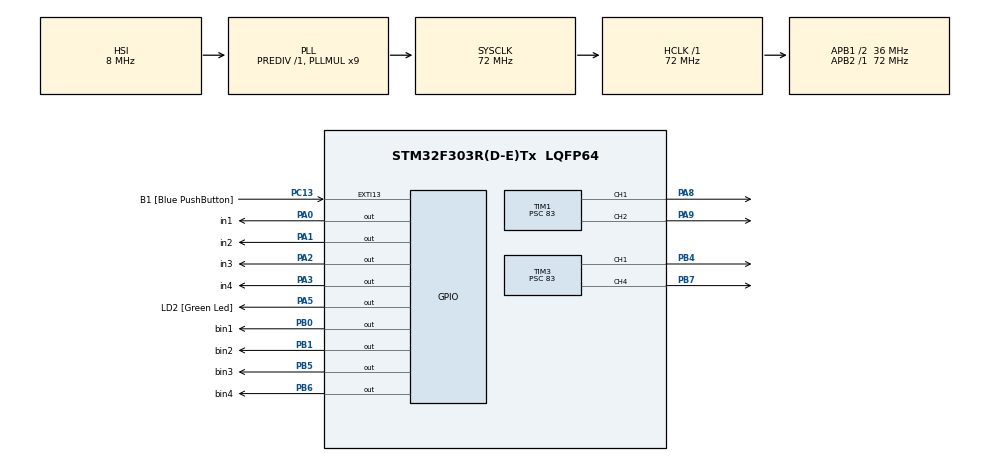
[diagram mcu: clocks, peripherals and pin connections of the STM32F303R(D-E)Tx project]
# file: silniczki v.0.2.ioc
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Mcu.Family=STM32F3
Mcu.Name=STM32F303R(D-E)Tx
Mcu.Package=LQFP64
NVIC.PriorityGroup=NVIC_PRIORITYGROUP_0
PA0.GPIO_Label=in1
PA0.Signal=GPIO_Output
PA1.GPIO_Label=in2
PA1.Signal=GPIO_Output
PA13.GPIO_Label=TMS
PA13.Mode=Serial_Wire
PA13.Signal=SYS_JTMS-SWDIO
PA14.GPIO_Label=TCK
PA14.Mode=Serial_Wire
PA14.Signal=SYS_JTCK-SWCLK
PA2.GPIO_Label=in3
PA2.Signal=GPIO_Output
PA3.GPIO_Label=in4
PA3.Signal=GPIO_Output
PA5.GPIO_Label=LD2 [Green Led]
PA5.GPIO_Mode=GPIO_MODE_OUTPUT_PP
PA5.GPIO_PuPd=GPIO_NOPULL
PA5.GPIO_Speed=GPIO_SPEED_FREQ_LOW
PA5.Signal=GPIO_Output
PA8.Signal=S_TIM1_CH1
PA9.Signal=S_TIM1_CH2
PB0.GPIO_Label=bin1
PB0.Signal=GPIO_Output
PB1.GPIO_Label=bin2
PB1.Signal=GPIO_Output
PB3.GPIO_Label=SWO
PB3.Signal=SYS_JTDO-TRACESWO
PB4.Signal=S_TIM3_CH1
PB5.GPIO_Label=bin3
PB5.Signal=GPIO_Output
PB6.GPIO_Label=bin4
PB6.Signal=GPIO_Output
PB7.Signal=S_TIM3_CH4
PC13.GPIO_Label=B1 [Blue PushButton]
PC13.GPIO_ModeDefaultEXTI=GPIO_MODE_IT_FALLING
PC13.Signal=GPXTI13
PC14-OSC32_IN.Mode=LSE-External-Oscillator
PC14-OSC32_IN.Signal=RCC_OSC32_IN
PC15-OSC32_OUT.Mode=LSE-External-Oscillator
PC15-OSC32_OUT.Signal=RCC_OSC32_OUT
PF0-OSC_IN.Mode=HSE-External-Clock-Source
PF0-OSC_IN.Signal=RCC_OSC_IN
PF1-OSC_OUT.Signal=RCC_OSC_OUT
ProjectManager.HeapSize=0x200
ProjectManager.StackSize=0x400
ProjectManager.TargetToolchain=STM32CubeIDE
RCC.AHBFreq_Value=72000000
RCC.APB1CLKDivider=RCC_HCLK_DIV2
RCC.APB1Freq_Value=36000000
RCC.APB1TimFreq_Value=72000000
RCC.APB2Freq_Value=72000000
RCC.APB2TimFreq_Value=72000000
RCC.CortexFreq_Value=72000000
RCC.HCLKFreq_Value=72000000
RCC.HSE_VALUE=8000000
RCC.HSI_VALUE=8000000
RCC.PLLM=8
RCC.PLLMUL=RCC_PLL_MUL9
RCC.PLLN=336
RCC.PLLP=RCC_PLLP_DIV4
RCC.PLLQ=7
RCC.RCC_PLLsource_Clock_Source_FROM_HSE=RCC_HSE_PREDIV_DIV2
RCC.SYSCLKFreq_VALUE=72000000
RCC.SYSCLKSourceVirtual=RCC_SYSCLKSOURCE_PLLCLK
RCC.USBFreq_Value=72000000
SH.S_TIM1_CH1.0=TIM1_CH1,PWM Generation1 CH1
SH.S_TIM1_CH2.0=TIM1_CH2,PWM Generation2 CH2
SH.S_TIM3_CH1.0=TIM3_CH1,PWM Generation1 CH1
SH.S_TIM3_CH4.0=TIM3_CH4,PWM Generation4 CH4
TIM1.AutoReloadPreload=TIM_AUTORELOAD_PRELOAD_ENABLE
TIM1.Channel-PWM\ Generation1\ CH1=TIM_CHANNEL_1
TIM1.Channel-PWM\ Generation2\ CH2=TIM_CHANNEL_2
TIM1.Period=1000
TIM1.Prescaler=83
TIM3.AutoReloadPreload=TIM_AUTORELOAD_PRELOAD_ENABLE
TIM3.Channel-PWM\ Generation1\ CH1=TIM_CHANNEL_1
TIM3.Channel-PWM\ Generation4\ CH4=TIM_CHANNEL_4
TIM3.Period=1000
TIM3.Prescaler=83
VP_TIM1_VS_ClockSourceINT.Mode=Internal
VP_TIM3_VS_ClockSourceINT.Mode=Internal
board=NUCLEO-F303RE

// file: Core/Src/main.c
/* USER CODE BEGIN Header */
/**
  ******************************************************************************
  * @file           : main.c
  * @brief          : Main program body
  ******************************************************************************
  * @attention
  *
  * Copyright (c) 2025 STMicroelectronics.
  * All rights reserved.
  *
  * This software is licensed under terms that can be found in the LICENSE file
  * in the root directory of this software component.
  * If no LICENSE file comes with this software, it is provided AS-IS.
  *
  ******************************************************************************
  */
/* USER CODE END Header */
#include "main.h"

TIM_HandleTypeDef htim1;
TIM_HandleTypeDef htim3;

void SystemClock_Config(void);
static void MX_GPIO_Init(void);
static void MX_TIM1_Init(void);
static void MX_TIM3_Init(void);

int main(void)
{
  HAL_Init();
  SystemClock_Config();
  MX_GPIO_Init();
  MX_TIM1_Init();
  MX_TIM3_Init();

  /* Infinite loop */
  /* USER CODE BEGIN WHILE */
  while (1)
  {
	  // Silnik M1 do przodu
	  HAL_GPIO_WritePin(in1_GPIO_Port, in1_Pin, GPIO_PIN_SET);
	  HAL_GPIO_WritePin(in2_GPIO_Port, in2_Pin, GPIO_PIN_RESET);

	  // Silnik M2 do tyłu
	  HAL_GPIO_WritePin(in3_GPIO_Port, in3_Pin, GPIO_PIN_RESET);
	  HAL_GPIO_WritePin(in4_GPIO_Port, in4_Pin, GPIO_PIN_SET);

	  // Silnik M3 do przodu
	  HAL_GPIO_WritePin(bin1_GPIO_Port, bin1_Pin, GPIO_PIN_SET);
	  HAL_GPIO_WritePin(bin2_GPIO_Port, bin2_Pin, GPIO_PIN_RESET);

	  // Silnik M4 do tyłu
	  HAL_GPIO_WritePin(bin3_GPIO_Port, bin3_Pin, GPIO_PIN_RESET);
	  HAL_GPIO_WritePin(bin4_GPIO_Port, bin4_Pin, GPIO_PIN_SET);

  }
  /* USER CODE END WHILE */

}

void SystemClock_Config(void)
{
  RCC_OscInitTypeDef RCC_OscInitStruct = {0};
  RCC_ClkInitTypeDef RCC_ClkInitStruct = {0};
  RCC_PeriphCLKInitTypeDef PeriphClkInit = {0};

  /** Initializes the RCC Oscillators according to the specified parameters
  * in the RCC_OscInitTypeDef structure.
  */
  RCC_OscInitStruct.OscillatorType = RCC_OSCILLATORTYPE_HSI;
  RCC_OscInitStruct.HSIState = RCC_HSI_ON;
  RCC_OscInitStruct.HSICalibrationValue = RCC_HSICALIBRATION_DEFAULT;
  RCC_OscInitStruct.PLL.PLLState = RCC_PLL_ON;
  RCC_OscInitStruct.PLL.PLLSource = RCC_PLLSOURCE_HSI;
  RCC_OscInitStruct.PLL.PLLMUL = RCC_PLL_MUL9;
  RCC_OscInitStruct.PLL.PREDIV = RCC_PREDIV_DIV1;
  if (HAL_RCC_OscConfig(&RCC_OscInitStruct) != HAL_OK)
  {
    Error_Handler();
  }

  /** Initializes the CPU, AHB and APB buses clocks
  */
  RCC_ClkInitStruct.ClockType = RCC_CLOCKTYPE_HCLK|RCC_CLOCKTYPE_SYSCLK
                              |RCC_CLOCKTYPE_PCLK1|RCC_CLOCKTYPE_PCLK2;
  RCC_ClkInitStruct.SYSCLKSource = RCC_SYSCLKSOURCE_PLLCLK;
  RCC_ClkInitStruct.AHBCLKDivider = RCC_SYSCLK_DIV1;
  RCC_ClkInitStruct.APB1CLKDivider = RCC_HCLK_DIV2;
  RCC_ClkInitStruct.APB2CLKDivider = RCC_HCLK_DIV1;

  if (HAL_RCC_ClockConfig(&RCC_ClkInitStruct, FLASH_LATENCY_2) != HAL_OK)
  {
    Error_Handler();
  }
  PeriphClkInit.PeriphClockSelection = RCC_PERIPHCLK_TIM1|RCC_PERIPHCLK_TIM34;
  PeriphClkInit.Tim1ClockSelection = RCC_TIM1CLK_HCLK;
  PeriphClkInit.Tim34ClockSelection = RCC_TIM34CLK_HCLK;
  if (HAL_RCCEx_PeriphCLKConfig(&PeriphClkInit) != HAL_OK)
  {
    Error_Handler();
  }
}

static void MX_TIM1_Init(void)
{

  TIM_ClockConfigTypeDef sClockSourceConfig = {0};
  TIM_MasterConfigTypeDef sMasterConfig = {0};
  TIM_OC_InitTypeDef sConfigOC = {0};
  TIM_BreakDeadTimeConfigTypeDef sBreakDeadTimeConfig = {0};

  htim1.Instance = TIM1;
  htim1.Init.Prescaler = 83;
  htim1.Init.CounterMode = TIM_COUNTERMODE_UP;
  htim1.Init.Period = 1000;
  htim1.Init.ClockDivision = TIM_CLOCKDIVISION_DIV1;
  htim1.Init.RepetitionCounter = 0;
  htim1.Init.AutoReloadPreload = TIM_AUTORELOAD_PRELOAD_ENABLE;
  if (HAL_TIM_Base_Init(&htim1) != HAL_OK)
  {
    Error_Handler();
  }
  sClockSourceConfig.ClockSource = TIM_CLOCKSOURCE_INTERNAL;
  if (HAL_TIM_ConfigClockSource(&htim1, &sClockSourceConfig) != HAL_OK)
  {
    Error_Handler();
  }
  if (HAL_TIM_PWM_Init(&htim1) != HAL_OK)
  {
    Error_Handler();
  }
  sMasterConfig.MasterOutputTrigger = TIM_TRGO_RESET;
  sMasterConfig.MasterOutputTrigger2 = TIM_TRGO2_RESET;
  sMasterConfig.MasterSlaveMode = TIM_MASTERSLAVEMODE_DISABLE;
  if (HAL_TIMEx_MasterConfigSynchronization(&htim1, &sMasterConfig) != HAL_OK)
  {
    Error_Handler();
  }
  sConfigOC.OCMode = TIM_OCMODE_PWM1;
  sConfigOC.Pulse = 0;
  sConfigOC.OCPolarity = TIM_OCPOLARITY_HIGH;
  sConfigOC.OCNPolarity = TIM_OCNPOLARITY_HIGH;
  sConfigOC.OCFastMode = TIM_OCFAST_DISABLE;
  sConfigOC.OCIdleState = TIM_OCIDLESTATE_RESET;
  sConfigOC.OCNIdleState = TIM_OCNIDLESTATE_RESET;
  if (HAL_TIM_PWM_ConfigChannel(&htim1, &sConfigOC, TIM_CHANNEL_1) != HAL_OK)
  {
    Error_Handler();
  }
  if (HAL_TIM_PWM_ConfigChannel(&htim1, &sConfigOC, TIM_CHANNEL_2) != HAL_OK)
  {
    Error_Handler();
  }
  sBreakDeadTimeConfig.OffStateRunMode = TIM_OSSR_DISABLE;
  sBreakDeadTimeConfig.OffStateIDLEMode = TIM_OSSI_DISABLE;
  sBreakDeadTimeConfig.LockLevel = TIM_LOCKLEVEL_OFF;
  sBreakDeadTimeConfig.DeadTime = 0;
  sBreakDeadTimeConfig.BreakState = TIM_BREAK_DISABLE;
  sBreakDeadTimeConfig.BreakPolarity = TIM_BREAKPOLARITY_HIGH;
  sBreakDeadTimeConfig.BreakFilter = 0;
  sBreakDeadTimeConfig.Break2State = TIM_BREAK2_DISABLE;
  sBreakDeadTimeConfig.Break2Polarity = TIM_BREAK2POLARITY_HIGH;
  sBreakDeadTimeConfig.Break2Filter = 0;
  sBreakDeadTimeConfig.AutomaticOutput = TIM_AUTOMATICOUTPUT_DISABLE;
  if (HAL_TIMEx_ConfigBreakDeadTime(&htim1, &sBreakDeadTimeConfig) != HAL_OK)
  {
    Error_Handler();
  }
  HAL_TIM_MspPostInit(&htim1);

}

static void MX_TIM3_Init(void)
{

  TIM_ClockConfigTypeDef sClockSourceConfig = {0};
  TIM_MasterConfigTypeDef sMasterConfig = {0};
  TIM_OC_InitTypeDef sConfigOC = {0};

  htim3.Instance = TIM3;
  htim3.Init.Prescaler = 83;
  htim3.Init.CounterMode = TIM_COUNTERMODE_UP;
  htim3.Init.Period = 1000;
  htim3.Init.ClockDivision = TIM_CLOCKDIVISION_DIV1;
  htim3.Init.AutoReloadPreload = TIM_AUTORELOAD_PRELOAD_ENABLE;
  if (HAL_TIM_Base_Init(&htim3) != HAL_OK)
  {
    Error_Handler();
  }
  sClockSourceConfig.ClockSource = TIM_CLOCKSOURCE_INTERNAL;
  if (HAL_TIM_ConfigClockSource(&htim3, &sClockSourceConfig) != HAL_OK)
  {
    Error_Handler();
  }
  if (HAL_TIM_PWM_Init(&htim3) != HAL_OK)
  {
    Error_Handler();
  }
  sMasterConfig.MasterOutputTrigger = TIM_TRGO_RESET;
  sMasterConfig.MasterSlaveMode = TIM_MASTERSLAVEMODE_DISABLE;
  if (HAL_TIMEx_MasterConfigSynchronization(&htim3, &sMasterConfig) != HAL_OK)
  {
    Error_Handler();
  }
  sConfigOC.OCMode = TIM_OCMODE_PWM1;
  sConfigOC.Pulse = 0;
  sConfigOC.OCPolarity = TIM_OCPOLARITY_HIGH;
  sConfigOC.OCFastMode = TIM_OCFAST_DISABLE;
  if (HAL_TIM_PWM_ConfigChannel(&htim3, &sConfigOC, TIM_CHANNEL_1) != HAL_OK)
  {
    Error_Handler();
  }
  if (HAL_TIM_PWM_ConfigChannel(&htim3, &sConfigOC, TIM_CHANNEL_4) != HAL_OK)
  {
    Error_Handler();
  }
  HAL_TIM_MspPostInit(&htim3);

}

static void MX_GPIO_Init(void)
{
  GPIO_InitTypeDef GPIO_InitStruct = {0};

  /* GPIO Ports Clock Enable */
  __HAL_RCC_GPIOC_CLK_ENABLE();
  __HAL_RCC_GPIOF_CLK_ENABLE();
  __HAL_RCC_GPIOA_CLK_ENABLE();
  __HAL_RCC_GPIOB_CLK_ENABLE();

  /*Configure GPIO pin Output Level */
  HAL_GPIO_WritePin(GPIOA, in1_Pin|in2_Pin|in3_Pin|in4_Pin
                          |LD2_Pin, GPIO_PIN_RESET);

  /*Configure GPIO pin Output Level */
  HAL_GPIO_WritePin(GPIOB, bin1_Pin|bin2_Pin|bin3_Pin|bin4_Pin, GPIO_PIN_RESET);

  /*Configure GPIO pin : B1_Pin */
  GPIO_InitStruct.Pin = B1_Pin;
  GPIO_InitStruct.Mode = GPIO_MODE_IT_FALLING;
  GPIO_InitStruct.Pull = GPIO_NOPULL;
  HAL_GPIO_Init(B1_GPIO_Port, &GPIO_InitStruct);

  /*Configure GPIO pins : in1_Pin in2_Pin in3_Pin in4_Pin
                           LD2_Pin */
  GPIO_InitStruct.Pin = in1_Pin|in2_Pin|in3_Pin|in4_Pin
                          |LD2_Pin;
  GPIO_InitStruct.Mode = GPIO_MODE_OUTPUT_PP;
  GPIO_InitStruct.Pull = GPIO_NOPULL;
  GPIO_InitStruct.Speed = GPIO_SPEED_FREQ_LOW;
  HAL_GPIO_Init(GPIOA, &GPIO_InitStruct);

  /*Configure GPIO pins : bin1_Pin bin2_Pin bin3_Pin bin4_Pin */
  GPIO_InitStruct.Pin = bin1_Pin|bin2_Pin|bin3_Pin|bin4_Pin;
  GPIO_InitStruct.Mode = GPIO_MODE_OUTPUT_PP;
  GPIO_InitStruct.Pull = GPIO_NOPULL;
  GPIO_InitStruct.Speed = GPIO_SPEED_FREQ_LOW;
  HAL_GPIO_Init(GPIOB, &GPIO_InitStruct);

}

void Error_Handler(void)
{
  __disable_irq();
  while (1)
  {
  }
}
